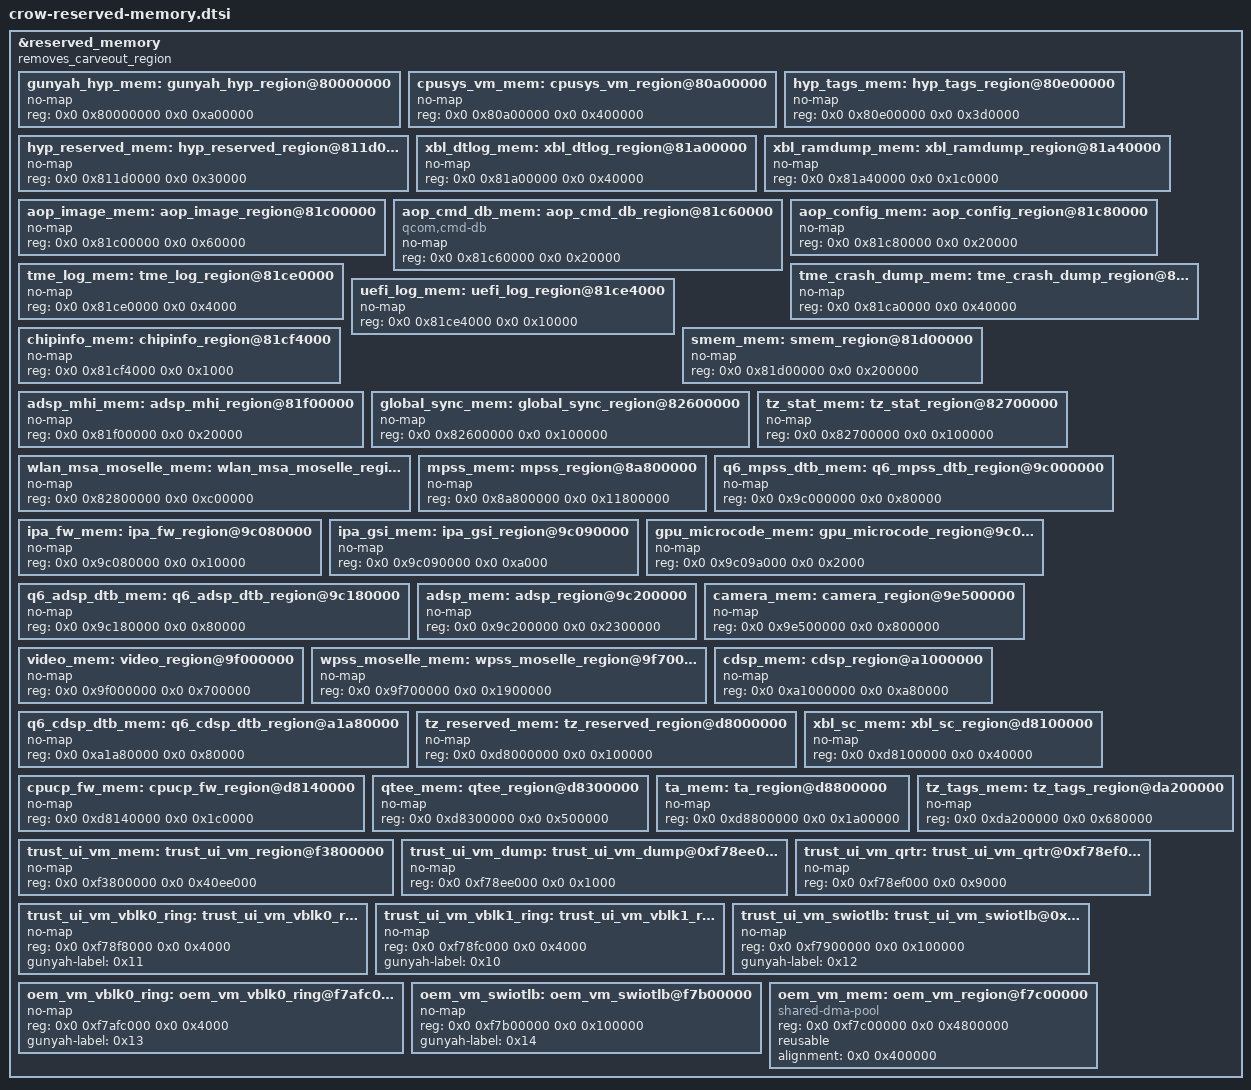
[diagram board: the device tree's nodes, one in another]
&reserved_memory {
	#address-cells = <2>;
	#size-cells = <2>;
	ranges;
	removes_carveout_region;

	gunyah_hyp_mem: gunyah_hyp_region@80000000 {
		no-map;
		reg = <0x0 0x80000000 0x0 0xa00000>;
	};

	cpusys_vm_mem: cpusys_vm_region@80a00000 {
		no-map;
		reg = <0x0 0x80a00000 0x0 0x400000>;
	};

	hyp_tags_mem: hyp_tags_region@80e00000 {
		no-map;
		reg = <0x0 0x80e00000 0x0 0x3d0000>;
	};

	hyp_reserved_mem: hyp_reserved_region@811d0000 {
		no-map;
		reg = <0x0 0x811d0000 0x0 0x30000>;
	};

	xbl_dtlog_mem: xbl_dtlog_region@81a00000 {
		no-map;
		reg = <0x0 0x81a00000 0x0 0x40000>;
	};

	xbl_ramdump_mem: xbl_ramdump_region@81a40000 {
		no-map;
		reg = <0x0 0x81a40000 0x0 0x1c0000>;
	};

	aop_image_mem: aop_image_region@81c00000 {
		no-map;
		reg = <0x0 0x81c00000 0x0 0x60000>;
	};

	aop_cmd_db_mem: aop_cmd_db_region@81c60000 {
		compatible = "qcom,cmd-db";
		no-map;
		reg = <0x0 0x81c60000 0x0 0x20000>;
	};

	aop_config_mem: aop_config_region@81c80000 {
		no-map;
		reg = <0x0 0x81c80000 0x0 0x20000>;
	};

	tme_crash_dump_mem: tme_crash_dump_region@81ca0000 {
		no-map;
		reg = <0x0 0x81ca0000 0x0 0x40000>;
	};

	tme_log_mem: tme_log_region@81ce0000 {
		no-map;
		reg = <0x0 0x81ce0000 0x0 0x4000>;
	};

	uefi_log_mem: uefi_log_region@81ce4000 {
		no-map;
		reg = <0x0 0x81ce4000 0x0 0x10000>;
	};

	chipinfo_mem: chipinfo_region@81cf4000 {
		no-map;
		reg = <0x0 0x81cf4000 0x0 0x1000>;
	};

	smem_mem: smem_region@81d00000 {
		no-map;
		reg = <0x0 0x81d00000 0x0 0x200000>;
	};

	adsp_mhi_mem: adsp_mhi_region@81f00000 {
		no-map;
		reg = <0x0 0x81f00000 0x0 0x20000>;
	};

	global_sync_mem: global_sync_region@82600000 {
		no-map;
		reg = <0x0 0x82600000 0x0 0x100000>;
	};

	tz_stat_mem: tz_stat_region@82700000 {
		no-map;
		reg = <0x0 0x82700000 0x0 0x100000>;
	};

	wlan_msa_moselle_mem: wlan_msa_moselle_region@82800000 {
		no-map;
		reg = <0x0 0x82800000 0x0 0xc00000>;
	};

	mpss_mem: mpss_region@8a800000 {
		no-map;
		reg = <0x0 0x8a800000 0x0 0x11800000>;
	};

	q6_mpss_dtb_mem: q6_mpss_dtb_region@9c000000 {
		no-map;
		reg = <0x0 0x9c000000 0x0 0x80000>;
	};

	ipa_fw_mem: ipa_fw_region@9c080000 {
		no-map;
		reg = <0x0 0x9c080000 0x0 0x10000>;
	};

	ipa_gsi_mem: ipa_gsi_region@9c090000 {
		no-map;
		reg = <0x0 0x9c090000 0x0 0xa000>;
	};

	gpu_microcode_mem: gpu_microcode_region@9c09a000 {
		no-map;
		reg = <0x0 0x9c09a000 0x0 0x2000>;
	};

	q6_adsp_dtb_mem: q6_adsp_dtb_region@9c180000 {
		no-map;
		reg = <0x0 0x9c180000 0x0 0x80000>;
	};

	adsp_mem: adsp_region@9c200000 {
		no-map;
		reg = <0x0 0x9c200000 0x0 0x2300000>;
	};

	camera_mem: camera_region@9e500000 {
		no-map;
		reg = <0x0 0x9e500000 0x0 0x800000>;
	};

	video_mem: video_region@9f000000 {
		no-map;
		reg = <0x0 0x9f000000 0x0 0x700000>;
	};

	wpss_moselle_mem: wpss_moselle_region@9f700000 {
		no-map;
		reg = <0x0 0x9f700000 0x0 0x1900000>;
	};

	cdsp_mem: cdsp_region@a1000000 {
		no-map;
		reg = <0x0 0xa1000000 0x0 0xa80000>;
	};

	q6_cdsp_dtb_mem: q6_cdsp_dtb_region@a1a80000 {
		no-map;
		reg = <0x0 0xa1a80000 0x0 0x80000>;
	};

	tz_reserved_mem: tz_reserved_region@d8000000 {
		no-map;
		reg = <0x0 0xd8000000 0x0 0x100000>;
	};

	xbl_sc_mem: xbl_sc_region@d8100000 {
		no-map;
		reg = <0x0 0xd8100000 0x0 0x40000>;
	};

	cpucp_fw_mem: cpucp_fw_region@d8140000 {
		no-map;
		reg = <0x0 0xd8140000 0x0 0x1c0000>;
	};

	qtee_mem: qtee_region@d8300000 {
		no-map;
		reg = <0x0 0xd8300000 0x0 0x500000>;
	};

	ta_mem: ta_region@d8800000 {
		no-map;
		reg = <0x0 0xd8800000 0x0 0x1a00000>;
	};

	tz_tags_mem: tz_tags_region@da200000 {
		no-map;
		reg = <0x0 0xda200000 0x0 0x680000>;
	};

	trust_ui_vm_mem: trust_ui_vm_region@f3800000 {
		no-map;
		reg = <0x0 0xf3800000 0x0 0x40ee000>;
	};

	trust_ui_vm_dump: trust_ui_vm_dump@0xf78ee000 {
		no-map;
		reg = <0x0 0xf78ee000 0x0 0x1000>;
	};

	trust_ui_vm_qrtr: trust_ui_vm_qrtr@0xf78ef000 {
		no-map;
		reg = <0x0 0xf78ef000 0x0 0x9000>;
	};

	trust_ui_vm_vblk0_ring: trust_ui_vm_vblk0_ring@0xf78f8000 {
		no-map;
		reg = <0x0 0xf78f8000 0x0 0x4000>;
		gunyah-label = <0x11>;                                  //for persist.img
	};

	trust_ui_vm_vblk1_ring: trust_ui_vm_vblk1_ring@0xf78fc000 {
		no-map;
		reg = <0x0 0xf78fc000 0x0 0x4000>;
		gunyah-label = <0x10>;                                  //for system.img
	};

	trust_ui_vm_swiotlb: trust_ui_vm_swiotlb@0xf7900000 {
		no-map;
		reg = <0x0 0xf7900000 0x0 0x100000>;
		gunyah-label = <0x12>;
	};

	oem_vm_vblk0_ring: oem_vm_vblk0_ring@f7afc000 {
		no-map;
		reg = <0x0 0xf7afc000 0x0 0x4000>;
		gunyah-label = <0x13>;
	};

	oem_vm_swiotlb: oem_vm_swiotlb@f7b00000 {
		no-map;
		reg = <0x0 0xf7b00000 0x0 0x100000>;
		gunyah-label = <0x14>;
	};

	oem_vm_mem: oem_vm_region@f7c00000 {
		compatible = "shared-dma-pool";
		reg = <0x0 0xf7c00000 0x0 0x4800000>;
		reusable;
		alignment = <0x0 0x400000>;
	};
};
